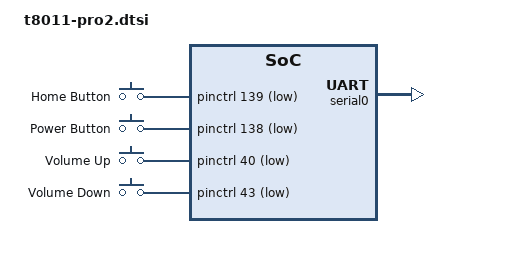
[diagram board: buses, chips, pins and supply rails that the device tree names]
// SPDX-License-Identifier: GPL-2.0+ OR MIT
/*
 * Apple iPad Pro 2 common device tree
 *
 * Copyright (c) 2022, Konrad Dybcio <konrad.dybcio@somainline.org>
 */

#include "t8011.dtsi"
#include <dt-bindings/input/input.h>

/ {
	gpio-keys {
		compatible = "gpio-keys";
		#address-cells = <1>;
		#size-cells = <0>;

		home {
			label = "Home Button";
			gpios = <&pinctrl 139 GPIO_ACTIVE_LOW>;
			linux,code = <KEY_LEFTMETA>;
		};

		power {
			label = "Power Button";
			gpios = <&pinctrl 138 GPIO_ACTIVE_LOW>;
			linux,code = <KEY_POWER>;
		};

		volume-up {
			label = "Volume Up";
			gpios = <&pinctrl 40 GPIO_ACTIVE_LOW>;
			linux,code = <KEY_VOLUMEUP>;
		};

		volume-down {
			label = "Volume Down";
			gpios = <&pinctrl 43 GPIO_ACTIVE_LOW>;
			linux,code = <KEY_VOLUMEDOWN>;
		};
	};
};

&serial0 {
	status = "okay";
};
